AUTOSAR XML (schema 00048)
package /HuaweiMDC/PlatformApplication/LidarCmCenterApplication/Execution
  executable liblidar_a_cm
    root sw component prototype liblidar_a_cm: application-type=liblidar_a_cm
package /HuaweiMDC/PlatformApplication/LidarCmCenterApplication/SwComponent
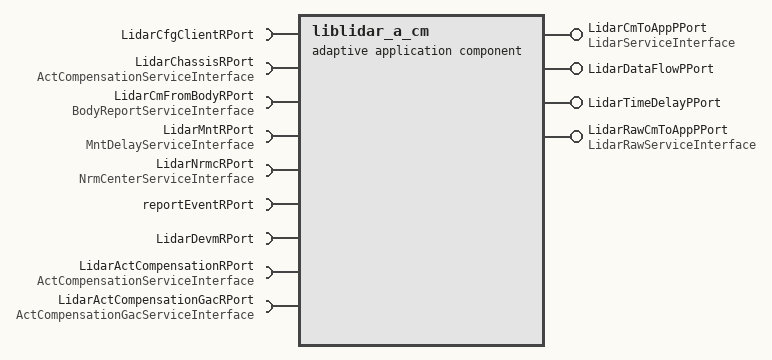
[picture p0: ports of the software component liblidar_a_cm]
  adaptive application sw component type liblidar_a_cm
    require port LidarCfgClientRPort
    require port LidarChassisRPort: required-interface=ActCompensationServiceInterface
    require port LidarCmFromBodyRPort: required-interface=BodyReportServiceInterface
    provide port LidarCmToAppPPort: provided-interface=LidarServiceInterface
    provide port LidarDataFlowPPort
    require port LidarMntRPort: required-interface=MntDelayServiceInterface
    require port LidarNrmcRPort: required-interface=NrmCenterServiceInterface
    provide port LidarTimeDelayPPort
    4 x require port:
      reportEventRPort
      LidarDevmRPort
      LidarActCompensationRPort: required-interface=ActCompensationServiceInterface
      LidarActCompensationGacRPort: required-interface=ActCompensationGacServiceInterface
    provide port LidarRawCmToAppPPort: provided-interface=LidarRawServiceInterface
  composition sw component type lidar_a
    component diag_agent: type=diag_agent
    component lidar_a_cm: type=liblidar_a_cm
